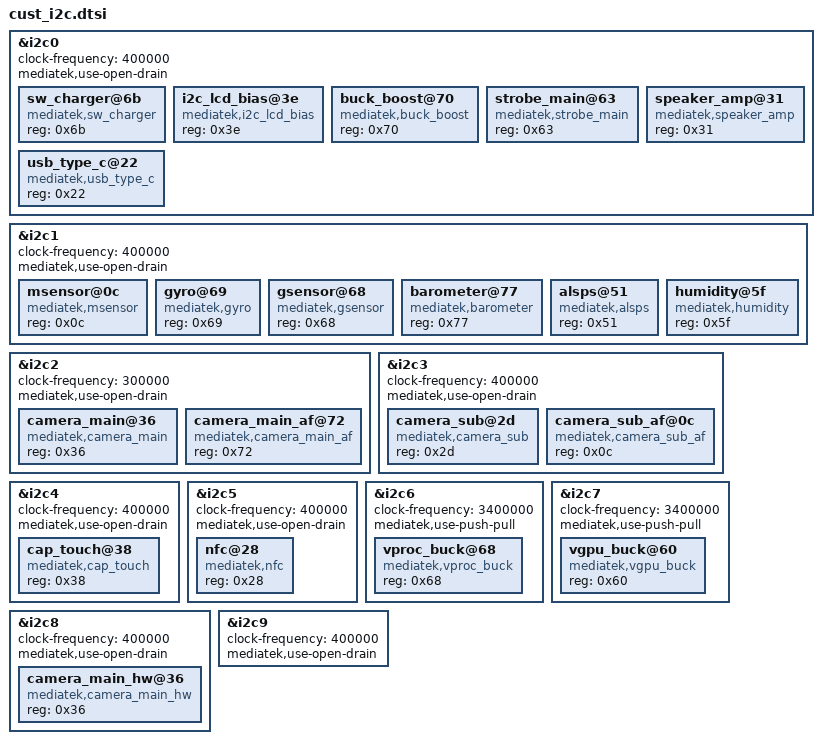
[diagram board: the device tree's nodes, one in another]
/*
 * Generated by MTK SP DrvGen Version: 2.2.160113 for MT6797. Copyright MediaTek Inc. (C) 2015.
 * 01.18.2022 23:42:18
 * Do Not Modify the File.
 */

/*************************
 * I2C DTSI File
*************************/

&i2c0 {
	#address-cells = <1>;
	#size-cells = <0>;
	clock-frequency = <400000>;
	mediatek,use-open-drain;
	sw_charger@6b {
		compatible = "mediatek,sw_charger";
		reg = <0x6b>;
		status = "okay";
	};
	i2c_lcd_bias@3e {
		compatible = "mediatek,i2c_lcd_bias";
		reg = <0x3e>;
		status = "okay";
	};
	buck_boost@70 {
		compatible = "mediatek,buck_boost";
		reg = <0x70>;
		status = "okay";
	};
	strobe_main@63 {
		compatible = "mediatek,strobe_main";
		reg = <0x63>;
		status = "okay";
	};
	speaker_amp@31 {
		compatible = "mediatek,speaker_amp";
		reg = <0x31>;
		status = "okay";
	};
	usb_type_c@22 {
		compatible = "mediatek,usb_type_c";
		reg = <0x22>;
		status = "okay";
	};
};

&i2c1 {
	#address-cells = <1>;
	#size-cells = <0>;
	clock-frequency = <400000>;
	mediatek,use-open-drain;
	msensor@0c {
		compatible = "mediatek,msensor";
		reg = <0x0c>;
		status = "okay";
	};
	gyro@69 {
		compatible = "mediatek,gyro";
		reg = <0x69>;
		status = "okay";
	};
	gsensor@68 {
		compatible = "mediatek,gsensor";
		reg = <0x68>;
		status = "okay";
	};
	barometer@77 {
		compatible = "mediatek,barometer";
		reg = <0x77>;
		status = "okay";
	};
	alsps@51 {
		compatible = "mediatek,alsps";
		reg = <0x51>;
		status = "okay";
	};
	humidity@5f {
		compatible = "mediatek,humidity";
		reg = <0x5f>;
		status = "okay";
	};
};

&i2c2 {
	#address-cells = <1>;
	#size-cells = <0>;
	clock-frequency = <300000>;
	mediatek,use-open-drain;
	camera_main@36 {
		compatible = "mediatek,camera_main";
		reg = <0x36>;
		status = "okay";
	};
	camera_main_af@72 {
		compatible = "mediatek,camera_main_af";
		reg = <0x72>;
		status = "okay";
	};
};

&i2c3 {
	#address-cells = <1>;
	#size-cells = <0>;
	clock-frequency = <400000>;
	mediatek,use-open-drain;
	camera_sub@2d {
		compatible = "mediatek,camera_sub";
		reg = <0x2d>;
		status = "okay";
	};
	camera_sub_af@0c {
		compatible = "mediatek,camera_sub_af";
		reg = <0x0c>;
		status = "okay";
	};
};

&i2c4 {
	#address-cells = <1>;
	#size-cells = <0>;
	clock-frequency = <400000>;
	mediatek,use-open-drain;
	cap_touch@38 {
		compatible = "mediatek,cap_touch";
		reg = <0x38>;
		status = "okay";
	};
};

&i2c5 {
	#address-cells = <1>;
	#size-cells = <0>;
	clock-frequency = <400000>;
	mediatek,use-open-drain;
	nfc@28 {
		compatible = "mediatek,nfc";
		reg = <0x28>;
		status = "okay";
	};
};

&i2c6 {
	#address-cells = <1>;
	#size-cells = <0>;
	clock-frequency = <3400000>;
	mediatek,use-push-pull;
	vproc_buck@68 {
		compatible = "mediatek,vproc_buck";
		reg = <0x68>;
		status = "okay";
	};
};

&i2c7 {
	#address-cells = <1>;
	#size-cells = <0>;
	clock-frequency = <3400000>;
	mediatek,use-push-pull;
	vgpu_buck@60 {
		compatible = "mediatek,vgpu_buck";
		reg = <0x60>;
		status = "okay";
	};
};

&i2c8 {
	#address-cells = <1>;
	#size-cells = <0>;
	clock-frequency = <400000>;
	mediatek,use-open-drain;
	camera_main_hw@36 {
		compatible = "mediatek,camera_main_hw";
		reg = <0x36>;
		status = "okay";
	};
};

&i2c9 {
	#address-cells = <1>;
	#size-cells = <0>;
	clock-frequency = <400000>;
	mediatek,use-open-drain;
};


